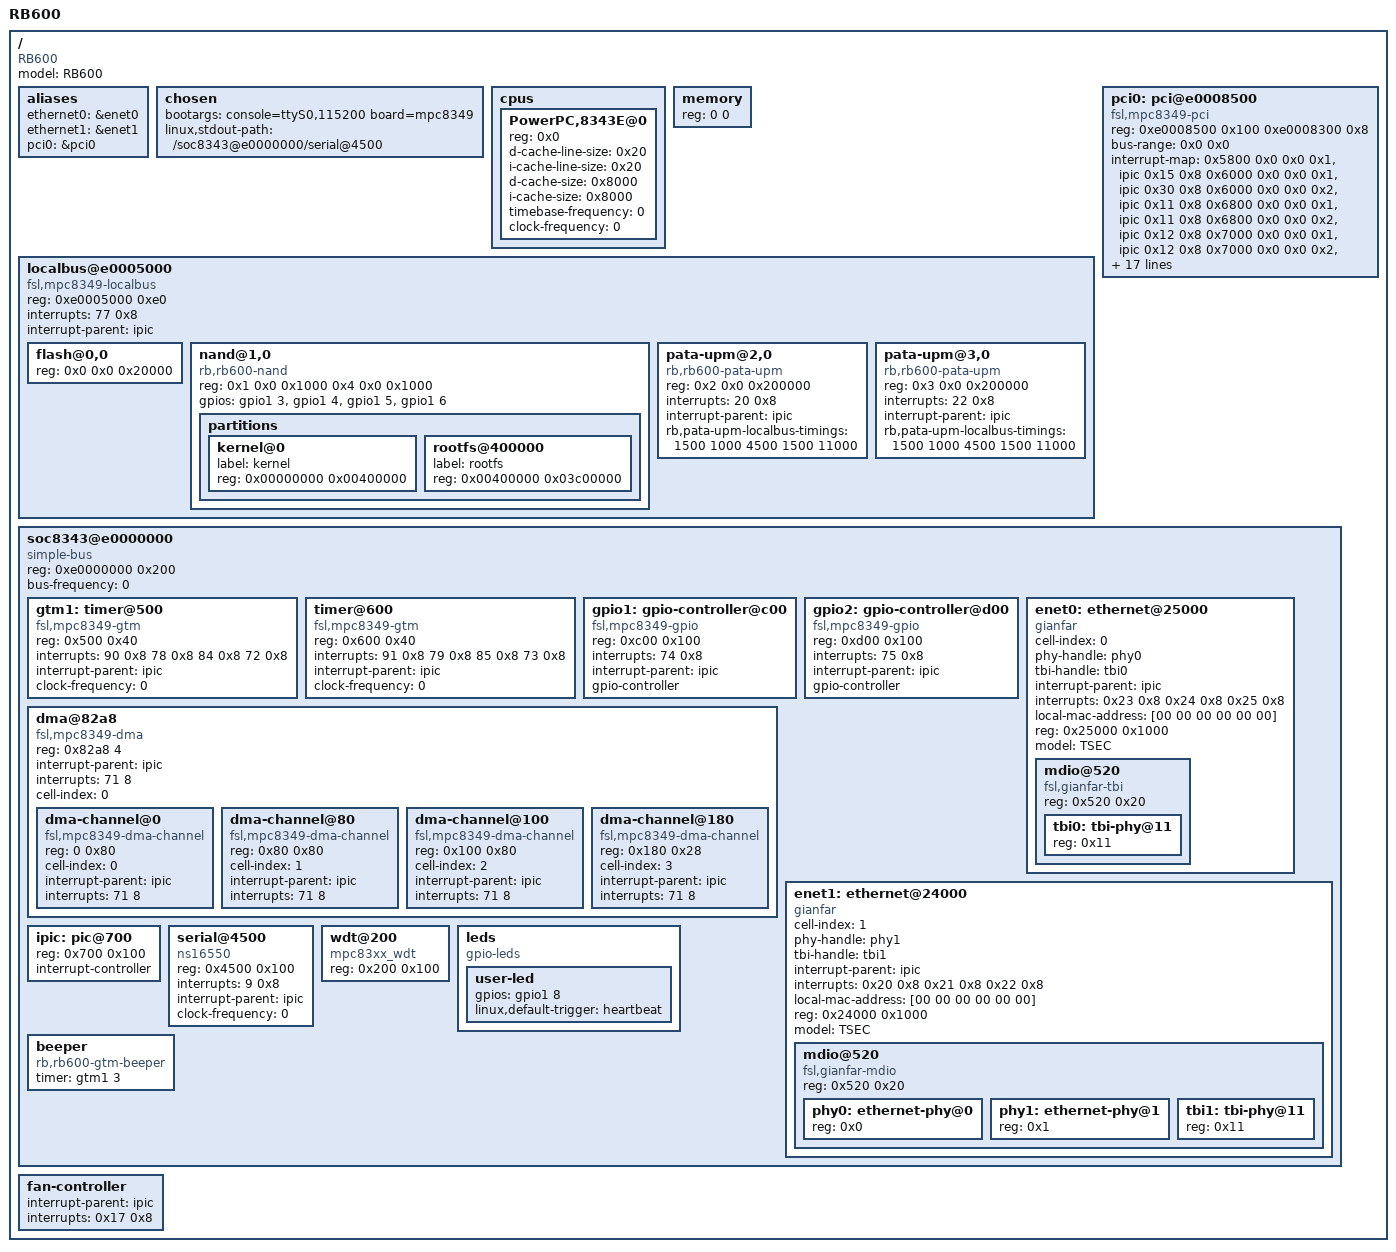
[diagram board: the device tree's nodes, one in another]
/*
 * RouterBOARD 600 series Device Tree Source
 *
 * Copyright (C) 2011 Noah Fontes <nfontes@invectorate.com>
 * Copyright (C) 2009 Michael Guntsche <mike@it-loops.com>
 *
 * This program is free software; you can redistribute  it and/or modify it
 * under  the terms of  the GNU General  Public License as published by the
 * Free Software Foundation;  either version 2 of the  License, or (at your
 * option) any later version.
 */

/dts-v1/;

/ {
	model = "RB600";
	compatible = "RB600", "RBPPC";
	#address-cells = <1>;
	#size-cells = <1>;

	aliases {
		ethernet0 = &enet0;
		ethernet1 = &enet1;
		pci0 = &pci0;
	};

	chosen {
		bootargs = "console=ttyS0,115200 board=mpc8349";
		linux,stdout-path = "/soc8343@e0000000/serial@4500";
	};

	cpus {
		#address-cells = <1>;
		#size-cells = <0>;

		PowerPC,8343E@0 {
			device_type = "cpu";
			reg = <0x0>;
			d-cache-line-size = <0x20>;
			i-cache-line-size = <0x20>;
			d-cache-size = <0x8000>;
			i-cache-size = <0x8000>;
			timebase-frequency = <0>; // Filled from the bootloader
			clock-frequency = <0>; // Filled from the bootloader
		};
	};

	memory {
		device_type = "memory";
		reg = <0 0>; // Filled from the bootloader
	};

	localbus@e0005000 {
		#address-cells = <2>;
		#size-cells = <1>;
		compatible = "fsl,mpc8349-localbus", "fsl,pq2pro-localbus", "simple-bus";
		reg = <0xe0005000 0xe0>;
		interrupts = <77 0x8>;
		interrupt-parent = <&ipic>;
		ranges = <
			0x0 0x0 0xff800000 0x00100000   // Flash, GPCM
			0x1 0x0 0xf8000000 0x00008000   // NAND (IO base), UPMA
			0x2 0x0 0xf9000000 0x00020000   // CompactFlash (ATA), UPMC
			0x3 0x0 0xf9200000 0x00020000   // CompactFlash (ATA), UPMC
			0x4 0x0 0xf0000000 0x00008000>; // NAND (nNAND?), UPMB

		flash@0,0 {
			reg = <0x0 0x0 0x20000>;
		};

		nand@1,0 {
			compatible = "rb,rb600-nand", "rb,nand";
			reg = <
				0x1 0x0 0x1000   // IO
				0x4 0x0 0x1000>; // Sync

			gpios = <
				&gpio1 3 0   // RNB
				&gpio1 4 0   // NCE
				&gpio1 5 0   // CLE
				&gpio1 6 0>; // ALE

			partitions {
				#address-cells = <1>;
				#size-cells = <1>;

				kernel@0 {
					label = "kernel";
					reg = <0x00000000 0x00400000>;
				};
				rootfs@400000 {
					label = "rootfs";
					reg = <0x00400000 0x03c00000>;
				};
			};
		};

		pata-upm@2,0 {
			compatible = "rb,rb600-pata-upm", "rb,pata-upm";
			reg = <0x2 0x0 0x200000>;
			interrupts = <20 0x8>;
			interrupt-parent = <&ipic>;

			rb,pata-upm-localbus-timings = <1500 1000 4500 1500 11000>;
		};

		pata-upm@3,0 {
			compatible = "rb,rb600-pata-upm", "rb,pata-upm";
			reg = <0x3 0x0 0x200000>;
			interrupts = <22 0x8>;
			interrupt-parent = <&ipic>;

			rb,pata-upm-localbus-timings = <1500 1000 4500 1500 11000>;
		};
	};

	pci0: pci@e0008500 {
		device_type = "pci";
		compatible = "fsl,mpc8349-pci";
		reg = <0xe0008500 0x100 0xe0008300 0x8>;
		#address-cells = <3>;
		#size-cells = <2>;
		#interrupt-cells = <1>;
		ranges = <0x2000000 0x0 0x80000000 0x80000000 0x0 0x20000000 0x1000000 0x0 0x0 0xd0000000 0x0 0x4000000>;
		bus-range = <0x0 0x0>;
		interrupt-map = <
			0x5800 0x0 0x0 0x1 &ipic 0x15 0x8
			0x6000 0x0 0x0 0x1 &ipic 0x30 0x8
			0x6000 0x0 0x0 0x2 &ipic 0x11 0x8
			0x6800 0x0 0x0 0x1 &ipic 0x11 0x8
			0x6800 0x0 0x0 0x2 &ipic 0x12 0x8
			0x7000 0x0 0x0 0x1 &ipic 0x12 0x8
			0x7000 0x0 0x0 0x2 &ipic 0x13 0x8
			0x7800 0x0 0x0 0x1 &ipic 0x13 0x8
			0x7800 0x0 0x0 0x2 &ipic 0x30 0x8
			0x8000 0x0 0x0 0x1 &ipic 0x30 0x8
			0x8000 0x0 0x0 0x2 &ipic 0x12 0x8
			0x8000 0x0 0x0 0x3 &ipic 0x11 0x8
			0x8000 0x0 0x0 0x4 &ipic 0x13 0x8
			0xa000 0x0 0x0 0x1 &ipic 0x30 0x8
			0xa000 0x0 0x0 0x2 &ipic 0x11 0x8
			0xa000 0x0 0x0 0x3 &ipic 0x12 0x8
			0xa000 0x0 0x0 0x4 &ipic 0x13 0x8
			0xa800 0x0 0x0 0x1 &ipic 0x11 0x8
			0xa800 0x0 0x0 0x2 &ipic 0x12 0x8
			0xa800 0x0 0x0 0x3 &ipic 0x13 0x8
			0xa800 0x0 0x0 0x4 &ipic 0x30 0x8>;
		interrupt-map-mask = <0xf800 0x0 0x0 0x7>;
		interrupt-parent = <&ipic>;
	};

	soc8343@e0000000 {
		#address-cells = <1>;
		#size-cells = <1>;
		device_type = "soc";
		compatible = "simple-bus";
		ranges = <0x0 0xe0000000 0x100000>;
		reg = <0xe0000000 0x200>;
		bus-frequency = <0>; // Filled from the bootloader

		gtm1: timer@500 {
			compatible = "fsl,mpc8349-gtm", "fsl,gtm";
			reg = <0x500 0x40>;
			interrupts = <90 0x8 78 0x8 84 0x8 72 0x8>;
			interrupt-parent = <&ipic>;
			clock-frequency = <0>; // Filled from the bootloader
		};

		timer@600 {
			compatible = "fsl,mpc8349-gtm", "fsl,gtm";
			reg = <0x600 0x40>;
			interrupts = <91 0x8 79 0x8 85 0x8 73 0x8>;
			interrupt-parent = <&ipic>;
			clock-frequency = <0>; // Filled from the bootloader
		};

		gpio1: gpio-controller@c00 {
			#gpio-cells = <2>;
			compatible = "fsl,mpc8349-gpio";
			reg = <0xc00 0x100>;
			interrupts = <74 0x8>;
			interrupt-parent = <&ipic>;
			gpio-controller;
		};

		gpio2: gpio-controller@d00 {
			#gpio-cells = <2>;
			compatible = "fsl,mpc8349-gpio";
			reg = <0xd00 0x100>;
			interrupts = <75 0x8>;
			interrupt-parent = <&ipic>;
			gpio-controller;
		};

		dma@82a8 {
			#address-cells = <1>;
			#size-cells = <1>;
			compatible = "fsl,mpc8349-dma", "fsl,elo-dma";
			reg = <0x82a8 4>;
			ranges = <0 0x8100 0x1a8>;
			interrupt-parent = <&ipic>;
			interrupts = <71 8>;
			cell-index = <0>;
			dma-channel@0 {
				compatible = "fsl,mpc8349-dma-channel", "fsl,elo-dma-channel";
				reg = <0 0x80>;
				cell-index = <0>;
				interrupt-parent = <&ipic>;
				interrupts = <71 8>;
			};
			dma-channel@80 {
				compatible = "fsl,mpc8349-dma-channel", "fsl,elo-dma-channel";
				reg = <0x80 0x80>;
				cell-index = <1>;
				interrupt-parent = <&ipic>;
				interrupts = <71 8>;
			};
			dma-channel@100 {
				compatible = "fsl,mpc8349-dma-channel", "fsl,elo-dma-channel";
				reg = <0x100 0x80>;
				cell-index = <2>;
				interrupt-parent = <&ipic>;
				interrupts = <71 8>;
			};
			dma-channel@180 {
				compatible = "fsl,mpc8349-dma-channel", "fsl,elo-dma-channel";
				reg = <0x180 0x28>;
				cell-index = <3>;
				interrupt-parent = <&ipic>;
				interrupts = <71 8>;
			};
		};

		enet0: ethernet@25000 {
			#address-cells = <1>;
			#size-cells = <1>;
			cell-index = <0>;
			phy-handle = <&phy0>;
			tbi-handle = <&tbi0>;
			interrupt-parent = <&ipic>;
			interrupts = <0x23 0x8 0x24 0x8 0x25 0x8>;
			local-mac-address = [00 00 00 00 00 00]; // Filled from the bootloader
			reg = <0x25000 0x1000>;
			ranges = <0x0 0x25000 0x1000>;
			compatible = "gianfar";
			model = "TSEC";
			device_type = "network";

			mdio@520 {
				#address-cells = <1>;
				#size-cells = <0>;
				compatible = "fsl,gianfar-tbi";
				reg = <0x520 0x20>;

				tbi0: tbi-phy@11 {
					reg = <0x11>;
					device_type = "tbi-phy";
				};
			};
		};

		enet1: ethernet@24000 {
			#address-cells = <1>;
			#size-cells = <1>;
			cell-index = <1>;
			phy-handle = <&phy1>;
			tbi-handle = <&tbi1>;
			interrupt-parent = <&ipic>;
			interrupts = <0x20 0x8 0x21 0x8 0x22 0x8>;
			local-mac-address = [00 00 00 00 00 00]; // Filled from the bootloader
			reg = <0x24000 0x1000>;
			ranges = <0x0 0x24000 0x1000>;
			compatible = "gianfar";
			model = "TSEC";
			device_type = "network";

			mdio@520 {
				#size-cells = <0x0>;
				#address-cells = <0x1>;
				reg = <0x520 0x20>;
				compatible = "fsl,gianfar-mdio";

				phy0: ethernet-phy@0 {
					device_type = "ethernet-phy";
					reg = <0x0>;
				};

				phy1: ethernet-phy@1 {
					device_type = "ethernet-phy";
					reg = <0x1>;
				};

				tbi1: tbi-phy@11 {
					reg = <0x11>;
					device_type = "tbi-phy";
				};
			};
		};

		ipic: pic@700 {
			#address-cells = <0>;
			#interrupt-cells = <2>;
			device_type = "ipic";
			reg = <0x700 0x100>;
			interrupt-controller;
		};

		serial@4500 {
			device_type = "serial";
			compatible = "ns16550";
			reg = <0x4500 0x100>;
			interrupts = <9 0x8>;
			interrupt-parent = <&ipic>;
			clock-frequency = <0>; // Filled from the bootloader
		};

		wdt@200 {
			device_type = "watchdog";
			compatible = "mpc83xx_wdt";
			reg = <0x200 0x100>;
		};

		leds {
			compatible = "gpio-leds";

			user-led {
				gpios = <&gpio1 8 0>;
				linux,default-trigger = "heartbeat";
			};
		};

		beeper {
			compatible = "rb,rb600-gtm-beeper", "rb,gtm-beeper";
			timer = <&gtm1 3>;
		};
	};

	fan-controller {
		interrupt-parent = <&ipic>;
		interrupts = <0x17 0x8>;
		//sense = <&gpio 0x7>;
		//fan_on = <&gpio 0x9>;
	};
};
